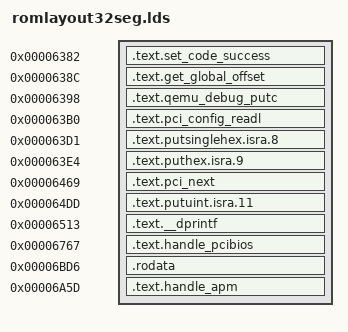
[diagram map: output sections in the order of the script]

/* DO NOT EDIT!  This is an autogenerated file.  See scripts/layoutrom.py. */
OUTPUT_FORMAT("elf32-i386")
OUTPUT_ARCH("i386")
SECTIONS
{
MaxPCIBus = 0x5e6c ;
DebugOutputPort = 0x6194 ;
PirAddr = 0x5e68 ;
entry_pcibios32 = 0xd1e4 ;
entry_apm16 = 0xd171 ;
entry_apm32 = 0xd1b2 ;
acpi_pm1a_cnt = 0x5e64 ;
.text.set_code_success 0x6382 : { *(.text.set_code_success) }
.text.get_global_offset 0x638c : { *(.text.get_global_offset) }
.text.qemu_debug_putc 0x6398 : { *(.text.qemu_debug_putc) }
.text.pci_config_readl 0x63b0 : { *(.text.pci_config_readl) }
.text.putsinglehex.isra.8 0x63d1 : { *(.text.putsinglehex.isra.8) }
.text.puthex.isra.9 0x63e4 : { *(.text.puthex.isra.9) }
.text.pci_next 0x6469 : { *(.text.pci_next) }
.text.putuint.isra.11 0x64dd : { *(.text.putuint.isra.11) }
.text.__dprintf 0x6513 : { *(.text.__dprintf) }
.text.handle_pcibios 0x6767 : { *(.text.handle_pcibios) }
.rodata 0x6bd6 : { *(.rodata) }
.text.handle_apm 0x6a5d : { *(.text.handle_apm) }


        /* Discard regular data sections to force a link error if
         * code attempts to access data not marked with VAR16 (or other
         * appropriate macro)
         */
        /DISCARD/ : {
                *(.text*) *(.data*) *(.bss*) *(.rodata*)
                *(COMMON) *(.discard*) *(.eh_frame) *(.note*)
                }
}
